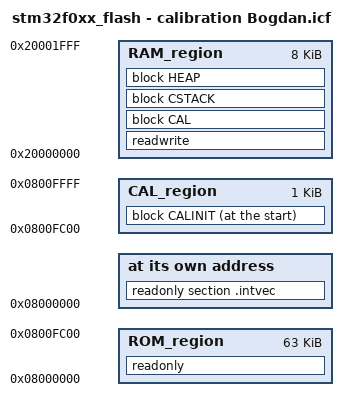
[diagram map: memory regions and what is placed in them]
/*###ICF### Section handled by ICF editor, don't touch! ****/
/*-Editor annotation file-*/
/* IcfEditorFile="$TOOLKIT_DIR$\config\ide\IcfEditor\cortex_v1_0.xml" */
/*-Specials-*/
define symbol __ICFEDIT_intvec_start__ = 0x08000000;
/*-Memory Regions-*/
define symbol __ICFEDIT_region_ROM_start__ = 0x08000000;
define symbol __ICFEDIT_region_ROM_end__   = 0x0800FC00;
define symbol __ICFEDIT_region_RAM_start__ = 0x20000000;
define symbol __ICFEDIT_region_RAM_end__   = 0x20001FFF;
/*-Sizes-*/
define symbol __ICFEDIT_size_cstack__ = 0x400;
define symbol __ICFEDIT_size_heap__   = 0x200;
/**** End of ICF editor section. ###ICF###*/


define memory mem with size = 4G;
define region CAL_region   = mem:[from 0x0800FC00 to 0x0800FFFF];
define region ROM_region   = mem:[from __ICFEDIT_region_ROM_start__   to __ICFEDIT_region_ROM_end__];
define region RAM_region   = mem:[from __ICFEDIT_region_RAM_start__   to __ICFEDIT_region_RAM_end__];
export symbol __ICFEDIT_region_RAM_start__;
export symbol __ICFEDIT_region_RAM_end__;
define block CSTACK    with alignment = 8, size = __ICFEDIT_size_cstack__   { };
define block HEAP      with alignment = 8, size = __ICFEDIT_size_heap__     { };
define block CALINIT { readonly section cal_init };
define block CAL { readwrite section cal };

initialize by copy { readwrite };
initialize by copy with packing = none { section cal };
do not initialize  { section .noinit };

place at address mem:__ICFEDIT_intvec_start__ { readonly section .intvec };

/*place at start of CAL_region   { readonly section cal_init }; */
place at start of CAL_region { block CALINIT };
place in ROM_region   { readonly };
place in RAM_region   { readwrite, block CAL,
                        block CSTACK, block HEAP };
